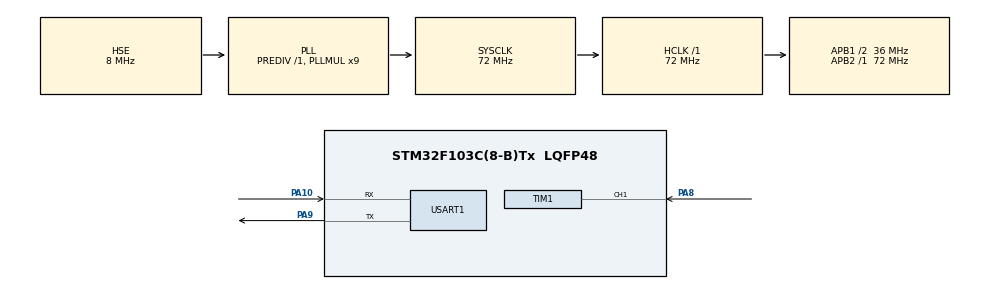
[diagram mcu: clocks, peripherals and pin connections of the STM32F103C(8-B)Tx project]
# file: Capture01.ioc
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Mcu.Family=STM32F1
Mcu.Name=STM32F103C(8-B)Tx
Mcu.Package=LQFP48
NVIC.PriorityGroup=NVIC_PRIORITYGROUP_4
NVIC.TIM1_CC_IRQn=true\:0\:0\:false\:false\:true\:true\:true
PA10.Mode=Asynchronous
PA10.Signal=USART1_RX
PA8.Signal=S_TIM1_CH1
PA9.Mode=Asynchronous
PA9.Signal=USART1_TX
PD0-OSC_IN.Mode=HSE-External-Oscillator
PD0-OSC_IN.Signal=RCC_OSC_IN
PD1-OSC_OUT.Mode=HSE-External-Oscillator
PD1-OSC_OUT.Signal=RCC_OSC_OUT
ProjectManager.HeapSize=0x800
ProjectManager.StackSize=0x800
ProjectManager.TargetToolchain=MDK-ARM V5
RCC.AHBFreq_Value=72000000
RCC.APB1CLKDivider=RCC_HCLK_DIV2
RCC.APB1Freq_Value=36000000
RCC.APB1TimFreq_Value=72000000
RCC.APB2Freq_Value=72000000
RCC.APB2TimFreq_Value=72000000
RCC.HCLKFreq_Value=72000000
RCC.PLLMUL=RCC_PLL_MUL9
RCC.PLLSourceVirtual=RCC_PLLSOURCE_HSE
RCC.SYSCLKFreq_VALUE=72000000
RCC.SYSCLKSource=RCC_SYSCLKSOURCE_PLLCLK
RCC.USBFreq_Value=72000000
SH.S_TIM1_CH1.0=TIM1_CH1,Input_Capture1_from_TI1
TIM1.AutoReloadPreload=TIM_AUTORELOAD_PRELOAD_ENABLE
TIM1.Channel-Input_Capture1_from_TI1=TIM_CHANNEL_1
TIM1.ICPolarity_CH1=TIM_INPUTCHANNELPOLARITY_RISING
TIM1.Period=0xFFFF
TIM1.Prescaler=1
USART1.VirtualMode=VM_ASYNC
VP_SYS_VS_ND.Mode=No_Debug
VP_TIM1_VS_ClockSourceINT.Mode=Internal
board=custom

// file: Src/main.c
/* USER CODE BEGIN Header */
/**
  ******************************************************************************
  * @file           : main.c
  * @brief          : Main program body
  ******************************************************************************
  * @attention
  *
  * <h2><center>&copy; Copyright (c) 2020 STMicroelectronics.
  * All rights reserved.</center></h2>
  *
  * This software component is licensed by ST under BSD 3-Clause license,
  * the "License"; You may not use this file except in compliance with the
  * License. You may obtain a copy of the License at:
  *                        opensource.org/licenses/BSD-3-Clause
  *
  ******************************************************************************
  */
/* USER CODE END Header */

#include "main.h"

TIM_HandleTypeDef htim1;

UART_HandleTypeDef huart1;

void SystemClock_Config(void);
static void MX_GPIO_Init(void);
static void MX_TIM1_Init(void);
static void MX_USART1_UART_Init(void);

/* USER CODE BEGIN 0 */

uint32_t uwIC2Value1 = 0;
uint32_t uwIC2Value2 = 0;
uint32_t uwDiffCapture = 0;

/* Capture index */
uint16_t uhCaptureIndex = 0;

/* Frequency Value */
uint32_t uwFrequency = 0;

uint16_t caps_max_count = 200;
uint16_t caps_pos = 0;
uint32_t caps[200];

struct __FILE
{
	int dummy;
};

FILE __stdout;

#ifdef __GNUC__
  /* With GCC/RAISONANCE, small printf (option LD Linker->Libraries->Small printf
     set to 'Yes') calls __io_putchar() */
  #define PUTCHAR_PROTOTYPE int __io_putchar(int ch)
#else
  #define PUTCHAR_PROTOTYPE int fputc(int ch, FILE *f)
#endif /* __GNUC__ */

PUTCHAR_PROTOTYPE
{
  /* Place your implementation of fputc here */
  /* e.g. write a character to the USART */
  HAL_UART_Transmit(&huart1, (uint8_t*) &ch, 1, 0x0fff);

  /* Loop until the end of transmission */
  //while (USART_GetFlagStatus(Port_USART, USART_FLAG_TC) == RESET)
  //{}

  return ch;
}

/* USER CODE END 0 */

int main(void)
{

  /* MCU Configuration--------------------------------------------------------*/

  /* Reset of all peripherals, Initializes the Flash interface and the Systick. */
  HAL_Init();

  /* Configure the system clock */
  SystemClock_Config();

  /* Initialize all configured peripherals */
  MX_GPIO_Init();
  MX_TIM1_Init();
  MX_USART1_UART_Init();
  /* USER CODE BEGIN 2 */

	HAL_TIM_IC_Start_IT(&htim1, TIM_CHANNEL_1);

	printf("Starting\n");

  /* USER CODE END 2 */

  /* Infinite loop */
  /* USER CODE BEGIN WHILE */
  while (1)
  {

		if(caps_pos >= caps_max_count)
		{
			for(int i=0;i<caps_max_count;i++)
			{
				printf("%d\n", caps[i]);
			}
			caps_pos = 0;
		}

    /* USER CODE END WHILE */

  }
}

void SystemClock_Config(void)
{
  RCC_OscInitTypeDef RCC_OscInitStruct = {0};
  RCC_ClkInitTypeDef RCC_ClkInitStruct = {0};

  /** Initializes the CPU, AHB and APB busses clocks
  */
  RCC_OscInitStruct.OscillatorType = RCC_OSCILLATORTYPE_HSE;
  RCC_OscInitStruct.HSEState = RCC_HSE_ON;
  RCC_OscInitStruct.HSEPredivValue = RCC_HSE_PREDIV_DIV1;
  RCC_OscInitStruct.HSIState = RCC_HSI_ON;
  RCC_OscInitStruct.PLL.PLLState = RCC_PLL_ON;
  RCC_OscInitStruct.PLL.PLLSource = RCC_PLLSOURCE_HSE;
  RCC_OscInitStruct.PLL.PLLMUL = RCC_PLL_MUL9;
  if (HAL_RCC_OscConfig(&RCC_OscInitStruct) != HAL_OK)
  {
    Error_Handler();
  }
  /** Initializes the CPU, AHB and APB busses clocks
  */
  RCC_ClkInitStruct.ClockType = RCC_CLOCKTYPE_HCLK|RCC_CLOCKTYPE_SYSCLK
                              |RCC_CLOCKTYPE_PCLK1|RCC_CLOCKTYPE_PCLK2;
  RCC_ClkInitStruct.SYSCLKSource = RCC_SYSCLKSOURCE_PLLCLK;
  RCC_ClkInitStruct.AHBCLKDivider = RCC_SYSCLK_DIV1;
  RCC_ClkInitStruct.APB1CLKDivider = RCC_HCLK_DIV2;
  RCC_ClkInitStruct.APB2CLKDivider = RCC_HCLK_DIV1;

  if (HAL_RCC_ClockConfig(&RCC_ClkInitStruct, FLASH_LATENCY_2) != HAL_OK)
  {
    Error_Handler();
  }
}

static void MX_TIM1_Init(void)
{

  TIM_ClockConfigTypeDef sClockSourceConfig = {0};
  TIM_MasterConfigTypeDef sMasterConfig = {0};
  TIM_IC_InitTypeDef sConfigIC = {0};

  htim1.Instance = TIM1;
  htim1.Init.Prescaler = 50;
  htim1.Init.CounterMode = TIM_COUNTERMODE_UP;
  htim1.Init.Period = 0xFFFF;
  htim1.Init.ClockDivision = TIM_CLOCKDIVISION_DIV1;
  htim1.Init.RepetitionCounter = 0;
  htim1.Init.AutoReloadPreload = TIM_AUTORELOAD_PRELOAD_ENABLE;
  if (HAL_TIM_Base_Init(&htim1) != HAL_OK)
  {
    Error_Handler();
  }
  sClockSourceConfig.ClockSource = TIM_CLOCKSOURCE_INTERNAL;
  if (HAL_TIM_ConfigClockSource(&htim1, &sClockSourceConfig) != HAL_OK)
  {
    Error_Handler();
  }
  if (HAL_TIM_IC_Init(&htim1) != HAL_OK)
  {
    Error_Handler();
  }
  sMasterConfig.MasterOutputTrigger = TIM_TRGO_RESET;
  sMasterConfig.MasterSlaveMode = TIM_MASTERSLAVEMODE_DISABLE;
  if (HAL_TIMEx_MasterConfigSynchronization(&htim1, &sMasterConfig) != HAL_OK)
  {
    Error_Handler();
  }
  sConfigIC.ICPolarity = TIM_INPUTCHANNELPOLARITY_BOTHEDGE;
  sConfigIC.ICSelection = TIM_ICSELECTION_DIRECTTI;
  sConfigIC.ICPrescaler = TIM_ICPSC_DIV1;
  sConfigIC.ICFilter = 0;
  if (HAL_TIM_IC_ConfigChannel(&htim1, &sConfigIC, TIM_CHANNEL_1) != HAL_OK)
  {
    Error_Handler();
  }

}

static void MX_USART1_UART_Init(void)
{

  huart1.Instance = USART1;
  huart1.Init.BaudRate = 115200;
  huart1.Init.WordLength = UART_WORDLENGTH_8B;
  huart1.Init.StopBits = UART_STOPBITS_1;
  huart1.Init.Parity = UART_PARITY_NONE;
  huart1.Init.Mode = UART_MODE_TX_RX;
  huart1.Init.HwFlowCtl = UART_HWCONTROL_NONE;
  huart1.Init.OverSampling = UART_OVERSAMPLING_16;
  if (HAL_UART_Init(&huart1) != HAL_OK)
  {
    Error_Handler();
  }

}

static void MX_GPIO_Init(void)
{

  /* GPIO Ports Clock Enable */
  __HAL_RCC_GPIOD_CLK_ENABLE();
  __HAL_RCC_GPIOA_CLK_ENABLE();

}

/* USER CODE BEGIN 4 */

void HAL_TIM_IC_CaptureCallback(TIM_HandleTypeDef *htim)
{
	if(uhCaptureIndex == 1)
	{
		uwIC2Value1 = HAL_TIM_ReadCapturedValue(htim, TIM_CHANNEL_1);
		uhCaptureIndex = 1;
	}
	else
	{
		uwIC2Value2 = HAL_TIM_ReadCapturedValue(htim, TIM_CHANNEL_1);

		if (uwIC2Value2 > uwIC2Value1)
		{
			uwDiffCapture = (uwIC2Value2 - uwIC2Value1);
		}
		else if (uwIC2Value2 < uwIC2Value1)
		{
			/* 0xFFFF is max TIM1_CCRx value */
			uwDiffCapture = ((0xFFFF - uwIC2Value1) + uwIC2Value2) + 1;
		}
		else
		{
			/* If capture values are equal, we have reached the limit of frequency
				 measures */
			;
		}

		if(caps_pos < caps_max_count)
		{
			caps[caps_pos] = uwDiffCapture;
			caps_pos++;
		}

		uhCaptureIndex = 0;
	}
}

/* USER CODE END 4 */

void Error_Handler(void)
{
}

/************************ (C) COPYRIGHT STMicroelectronics *****END OF FILE****/
